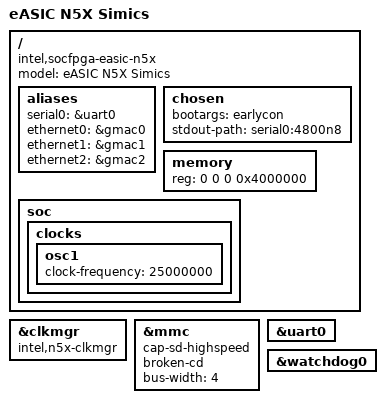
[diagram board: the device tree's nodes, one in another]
// SPDX-License-Identifier:     GPL-2.0
/*
 * Copyright (C) 2019, Intel Corporation
 */
#include "socfpga_agilex.dtsi"

/ {
	model = "eASIC N5X Simics";

	compatible = "intel,socfpga-easic-n5x";

	aliases {
		serial0 = &uart0;
		ethernet0 = &gmac0;
		ethernet1 = &gmac1;
		ethernet2 = &gmac2;
	};

	chosen {
		bootargs = "earlycon";
		stdout-path = "serial0:4800n8";
	};

	memory {
		device_type = "memory";
		/* We expect the bootloader to fill in the reg */
		reg = <0 0 0 0x4000000>;
	};

	soc {
		clocks {
			osc1 {
				clock-frequency = <25000000>;
			};
		};
	};
};

&clkmgr {
	compatible = "intel,n5x-clkmgr";
};

&mmc {
	status = "okay";
	cap-sd-highspeed;
	broken-cd;
	bus-width = <4>;
};

&uart0 {
	status = "okay";
};

&watchdog0 {
	status = "okay";
};
